# STM32U585 register map
File version: 2.2
CPU: CM33 r0p1, little endian, MPU, FPU, 4 interrupt priority bits
Registers are 32-bit, read-write, reset 0x0 unless marked. A register's access mark holds for its fields unless they carry their own. Offsets are from the block's base; [hi:lo] are bit positions; 'fields as' and 'values as' point back to an identical list.

## FMAC — Filter Math Accelerator
Base 0x40021400
Same registers: SEC_FMAC 0x50021400
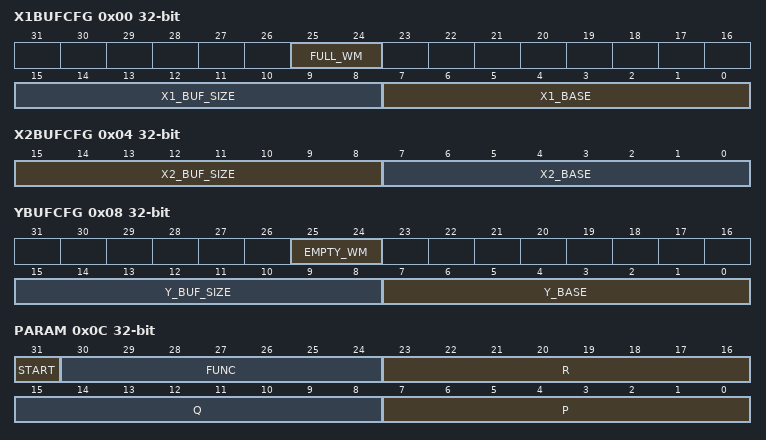
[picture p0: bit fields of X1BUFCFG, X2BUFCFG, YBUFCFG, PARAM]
0x00 X1BUFCFG — FMAC X1 Buffer Configuration register
  [25:24] FULL_WM — Watermark for buffer full flag
  [15:8] X1_BUF_SIZE — Allocated size of X1 buffer in 16-bit words
  [7:0] X1_BASE — Base address of X1 buffer
0x04 X2BUFCFG — FMAC X2 Buffer Configuration register
  [15:8] X2_BUF_SIZE — Size of X2 buffer in 16-bit words
  [7:0] X2_BASE — Base address of X2 buffer
0x08 YBUFCFG — FMAC Y Buffer Configuration register
  [25:24] EMPTY_WM — Watermark for buffer empty flag
  [15:8] Y_BUF_SIZE — Size of Y buffer in 16-bit words
  [7:0] Y_BASE — Base address of Y buffer
0x0C PARAM — FMAC Parameter register
  [31] START — Enable execution
  [30:24] FUNC — Function
  [23:16] R — Input parameter R
  [15:8] Q — Input parameter Q
  [7:0] P — Input parameter P
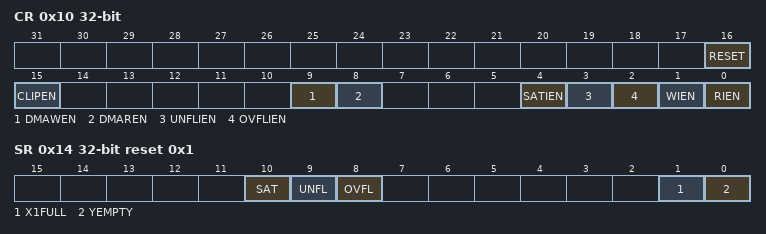
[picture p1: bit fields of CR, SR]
0x10 CR — FMAC Control register
  [16] RESET — Reset FMAC unit
  [15] CLIPEN — Enable clipping
  [9] DMAWEN — Enable DMA write channel requests
  [8] DMAREN — Enable DMA read channel requests
  [4] SATIEN — Enable saturation error interrupts
  [3] UNFLIEN — Enable underflow error interrupts
  [2] OVFLIEN — Enable overflow error interrupts
  [1] WIEN — Enable write interrupt
  [0] RIEN — Enable read interrupt
0x14 SR ro reset 0x1 — FMAC Status register
  [10] SAT — Saturation error flag
  [9] UNFL — Underflow error flag
  [8] OVFL — Overflow error flag
  [1] X1FULL — X1 buffer full flag
  [0] YEMPTY — Y buffer empty flag
0x18 WDATA wo — FMAC Write Data register
  [15:0] WDATA — Write data
0x1C RDATA ro — FMAC Read Data register
  [15:0] RDATA — Read data

## CORDIC — CORDIC Co-processor
Base 0x40021000
Same registers: SEC_CORDIC 0x50021000
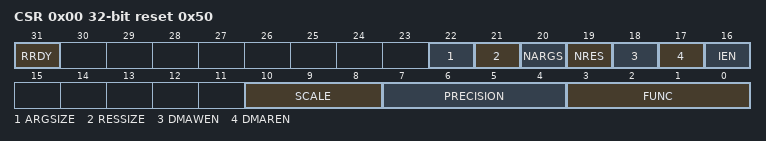
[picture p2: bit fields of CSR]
0x00 CSR access per field reset 0x50 — CORDIC Control Status register
  [31] RRDY ro — Result ready flag
  [22] ARGSIZE rw — Width of input data
  [21] RESSIZE rw — Width of output data
  [20] NARGS rw — Number of arguments expected by the CORDIC_WDATA register
  [19] NRES rw — Number of results in the CORDIC_RDATA register
  [18] DMAWEN rw — Enable DMA write channel
  [17] DMAREN rw — Enable DMA read channel
  [16] IEN rw — Enable interrupt
  [10:8] SCALE rw — Scaling factor
  [7:4] PRECISION rw — Precision required (number of iterations)
  [3:0] FUNC rw — Function
0x04 WDATA wo — FMAC Write Data register
  [31:0] ARG — Function input arguments
0x08 RDATA ro — FMAC Read Data register
  [31:0] RES — Function result

## OPAMP — Operational amplifiers
Base 0x46005000
Same registers: SEC_OPAMP 0x56005000
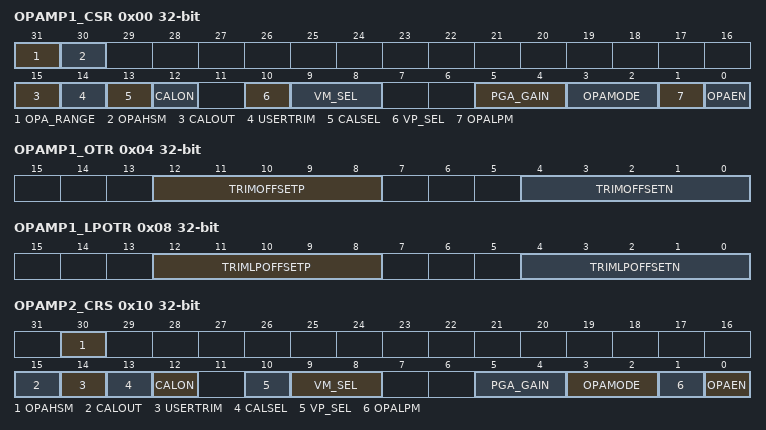
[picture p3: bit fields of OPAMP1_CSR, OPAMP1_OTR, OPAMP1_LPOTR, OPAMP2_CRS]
0x00 OPAMP1_CSR access per field — OPAMP1 control/status register
  [31] OPA_RANGE rw — OPAMP range setting
    1=OPAMP range set
  [30] OPAHSM rw — OPAMP high-speed mode
    0=normal mode (standard slew rate); 1=increased consumption to improve the slew rate
  [15] CALOUT ro — OPAMP calibration output
  [14] USERTRIM rw — factory' or user' offset trimmed values selection
    0=factory' trim code used; 1=user' trim code used
  [13] CALSEL rw — Calibration selection
    0=NMOS calibration (200 mV applied on OPAMP inputs); 1=PMOS calibration (Vless thansub>DDA less than/sub>- 200 mV applied on OPAMP inputs)
  [12] CALON rw — Calibration mode enable
    0=normal mode; 1=calibration mode (all switches opened by hardware)
  [10] VP_SEL rw — Non-inverted input selection
    0=GPIO connected to VINP; 1=DAC connected to VINP
  [9:8] VM_SEL rw — Inverting input selection
    0=GPIO connected to VINM (valid also in PGA mode for filtering); 1=dedicated low-leakage input connected to VINM (valid also in PGA mode for filtering)
  [5:4] PGA_GAIN rw — OPAMP programmable amplifier gain value
    0=internal PGA gain 2; 1=internal PGA gain 4; 2=internal PGA gain 8; 3=internal PGA gain 16
  [3:2] OPAMODE rw — OPAMP PGA mode
    2=internal PGA enabled, gain programmed in PGA_GAIN; 3=internal follower
  [1] OPALPM rw — OPAMP low-power mode
    0=normal mode; 1=low-power mode
  [0] OPAEN rw — OPAMP enable
    0=OPAMP disabled; 1=OPAMP enabled
0x04 OPAMP1_OTR (reset mask 0xFFFF0000) — OPAMP1 offset trimming register in normal mode
  [12:8] TRIMOFFSETP — Trim for PMOS differential pairs
  [4:0] TRIMOFFSETN — Trim for NMOS differential pairs
0x08 OPAMP1_LPOTR (reset mask 0xFFFF0000) — OPAMP1 offset trimming register in low-power mode
  [12:8] TRIMLPOFFSETP — Low-power mode trim for PMOS differential pairs
  [4:0] TRIMLPOFFSETN — Low-power mode trim for NMOS differential pairs
0x10 OPAMP2_CRS access per field — OPAMP2 control/status register
  [30] OPAHSM rw — OPAMP high-speed mode
    values as OPAMP1_CSR.OPAHSM
  [15] CALOUT ro — OPAMP calibration output
  [14] USERTRIM rw — factory' or user' offset trimmed values selection
    0=factory' trim code used; 1=user' trim code used
  [13] CALSEL rw — Calibration selection
    values as OPAMP1_CSR.CALSEL
  [12] CALON rw — Calibration mode enable
    values as OPAMP1_CSR.CALON
  [10] VP_SEL rw — Non inverted input selection
    0=GPIO connected to VINP; 1=DAC connected to VINP
  [9:8] VM_SEL rw — Inverting input selection
    0=GPIO connected to VINM (valid also in PGA mode for filtering); 1=dedicated low-leakage input connected to VINM (valid also
  [5:4] PGA_GAIN rw — OPAMP programmable amplifier gain value
    values as OPAMP1_CSR.PGA_GAIN
  [3:2] OPAMODE rw — OPAMP PGA mode
    values as OPAMP1_CSR.OPAMODE
  [1] OPALPM rw — OPAMP low-power mode
    0=normal mode; 1=low-power mode
  [0] OPAEN rw — OPAMP enable
    0=OPAMP disabled; 1=OPAMP enabled
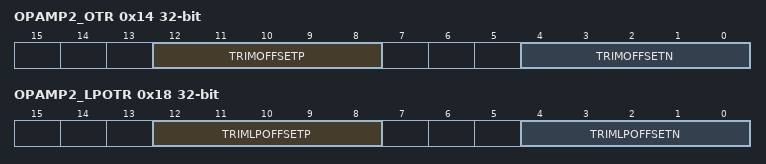
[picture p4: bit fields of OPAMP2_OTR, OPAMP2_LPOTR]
0x14 OPAMP2_OTR (reset mask 0xFFFF0000) — OPAMP2 offset trimming register in normal mode
  fields as OPAMP1_OTR
0x18 OPAMP2_LPOTR (reset mask 0xFFFF0000) — OPAMP2 offset trimming register in low-power mode
  fields as OPAMP1_LPOTR
